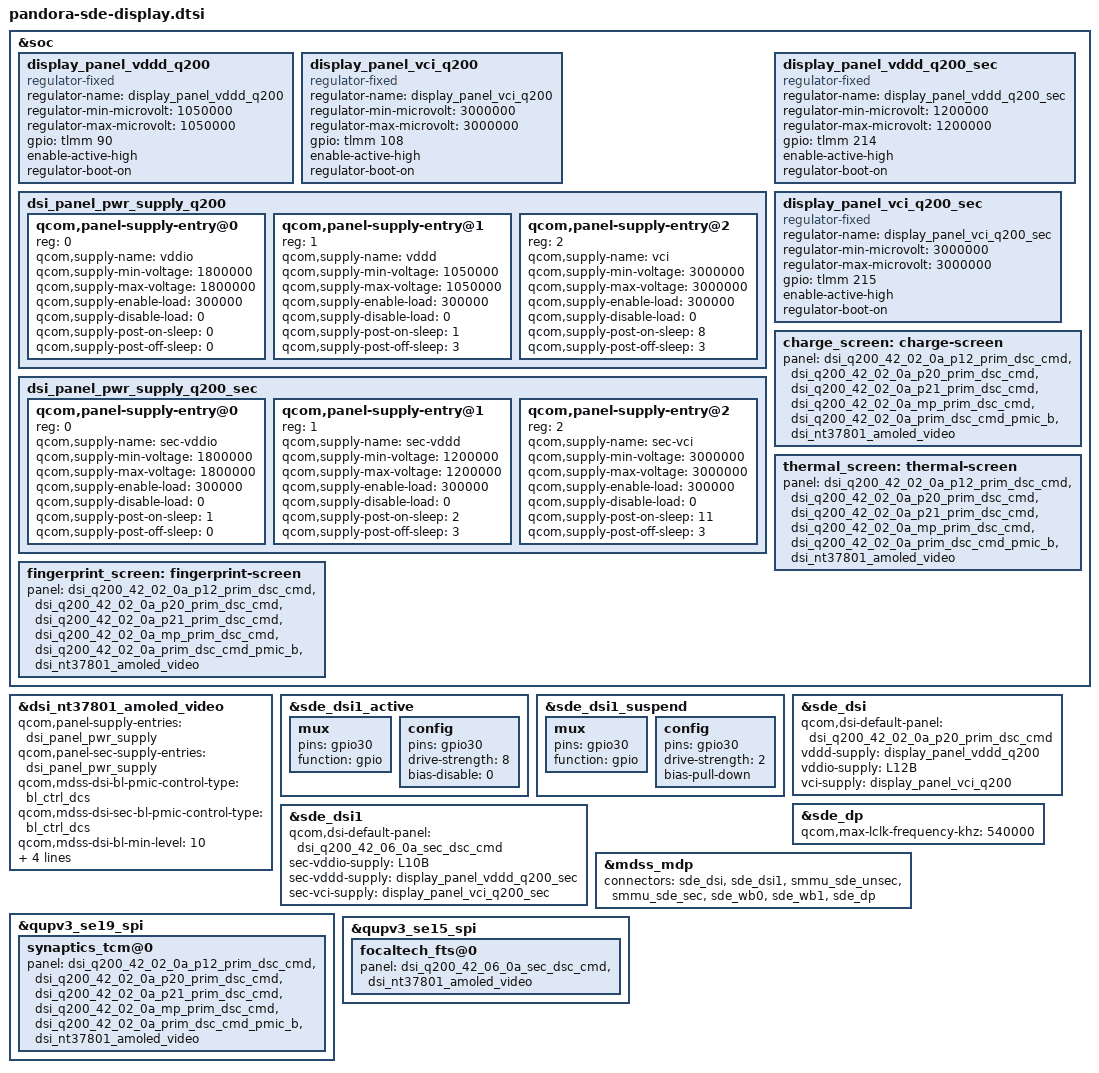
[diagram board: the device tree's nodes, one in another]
#include "canoe-sde-display.dtsi"
#include "dsi-panel-q200-42-02-0a-p12-prim-dsc-cmd.dtsi"
#include "dsi-panel-q200-42-02-0a-p20-prim-dsc-cmd.dtsi"
#include "dsi-panel-q200-42-02-0a-p21-prim-dsc-cmd.dtsi"
#include "dsi-panel-q200-42-02-0a-mp-prim-dsc-cmd.dtsi"
#include "dsi-panel-q200-42-02-0a-prim-dsc-cmd-pmic-b.dtsi"

#include "dsi-panel-q200-42-06-0a-sec-dsc-cmd.dtsi"

&soc {
	display_panel_vddd_q200: display_panel_vddd_q200 {
		compatible = "regulator-fixed";
		regulator-name = "display_panel_vddd_q200";
		regulator-min-microvolt = <1050000>;
		regulator-max-microvolt = <1050000>;
		gpio = <&tlmm 90 0>;
		enable-active-high;
		regulator-boot-on;
	};

    display_panel_vci_q200: display_panel_vci_q200 {
		compatible = "regulator-fixed";
		regulator-name = "display_panel_vci_q200";
		regulator-min-microvolt = <3000000>;
		regulator-max-microvolt = <3000000>;
		gpio = <&tlmm 108 0>;
		enable-active-high;
		regulator-boot-on;
	};

	dsi_panel_pwr_supply_q200: dsi_panel_pwr_supply_q200 {
		qcom,panel-supply-entry@0 {
			reg = <0>;
			qcom,supply-name = "vddio";
			qcom,supply-min-voltage = <1800000>;
			qcom,supply-max-voltage = <1800000>;
			qcom,supply-enable-load = <300000>;
			qcom,supply-disable-load = <0>;
			qcom,supply-post-on-sleep = <0>;
			qcom,supply-post-off-sleep = <0>;
		};
		qcom,panel-supply-entry@1 {
			reg = <1>;
			qcom,supply-name = "vddd";
			qcom,supply-min-voltage = <1050000>;
			qcom,supply-max-voltage = <1050000>;
			qcom,supply-enable-load = <300000>;
			qcom,supply-disable-load = <0>;
			qcom,supply-post-on-sleep = <1>;
			qcom,supply-post-off-sleep = <3>;
		};
		qcom,panel-supply-entry@2 {
			reg = <2>;
			qcom,supply-name = "vci";
			qcom,supply-min-voltage = <3000000>;
			qcom,supply-max-voltage = <3000000>;
			qcom,supply-enable-load = <300000>;
			qcom,supply-disable-load = <0>;
			qcom,supply-post-on-sleep = <8>;
			qcom,supply-post-off-sleep = <3>;
		};
	};

	display_panel_vddd_q200_sec: display_panel_vddd_q200_sec {
		compatible = "regulator-fixed";
		regulator-name = "display_panel_vddd_q200_sec";
		regulator-min-microvolt = <1200000>;
		regulator-max-microvolt = <1200000>;
		gpio = <&tlmm 214 0>;
		enable-active-high;
		regulator-boot-on;
	};

	display_panel_vci_q200_sec: display_panel_vci_q200_sec {
		compatible = "regulator-fixed";
		regulator-name = "display_panel_vci_q200_sec";
		regulator-min-microvolt = <3000000>;
		regulator-max-microvolt = <3000000>;
		gpio = <&tlmm 215 0>;
		enable-active-high;
		regulator-boot-on;
	};

	dsi_panel_pwr_supply_q200_sec: dsi_panel_pwr_supply_q200_sec {
		qcom,panel-supply-entry@0 {
			reg = <0>;
			qcom,supply-name = "sec-vddio";
			qcom,supply-min-voltage = <1800000>;
			qcom,supply-max-voltage = <1800000>;
			qcom,supply-enable-load = <300000>;
			qcom,supply-disable-load = <0>;
			qcom,supply-post-on-sleep = <1>;
			qcom,supply-post-off-sleep = <0>;
		};
		qcom,panel-supply-entry@1 {
			reg = <1>;
			qcom,supply-name = "sec-vddd";
			qcom,supply-min-voltage = <1200000>;
			qcom,supply-max-voltage = <1200000>;
			qcom,supply-enable-load = <300000>;
			qcom,supply-disable-load = <0>;
			qcom,supply-post-on-sleep = <2>;
			qcom,supply-post-off-sleep = <3>;
		};
		qcom,panel-supply-entry@2 {
			reg = <2>;
			qcom,supply-name = "sec-vci";
			qcom,supply-min-voltage = <3000000>;
			qcom,supply-max-voltage = <3000000>;
			qcom,supply-enable-load = <300000>;
			qcom,supply-disable-load = <0>;
			qcom,supply-post-on-sleep = <11>;
			qcom,supply-post-off-sleep = <3>;
		};
	};
};
&dsi_nt37801_amoled_video {
       qcom,panel-supply-entries = <&dsi_panel_pwr_supply>;
       qcom,panel-sec-supply-entries = <&dsi_panel_pwr_supply>;
       qcom,mdss-dsi-bl-pmic-control-type = "bl_ctrl_dcs";
       qcom,mdss-dsi-sec-bl-pmic-control-type = "bl_ctrl_dcs";
       qcom,mdss-dsi-bl-min-level = <10>;
       qcom,mdss-dsi-bl-max-level = <4095>;
       qcom,mdss-brightness-max-level = <8191>;
       qcom,mdss-dsi-bl-inverted-dbv;
       qcom,platform-sec-reset-gpio = <&tlmm 30 0>;
};

&sde_dsi1_active {
	mux {
		pins = "gpio30";
		function = "gpio";
	};

	config {
		pins = "gpio30";
		drive-strength = <8>;   /* 8 mA */
		bias-disable = <0>;   /* no pull */
	};
};

&sde_dsi1_suspend {
	mux {
		pins = "gpio30";
		function = "gpio";
	};

	config {
		pins = "gpio30";
		drive-strength = <2>;   /* 2 mA */
		bias-pull-down;         /* PULL DOWN */
	};
};

&sde_dsi {
	qcom,dsi-default-panel = <&dsi_q200_42_02_0a_p20_prim_dsc_cmd>;
	vddd-supply = <&display_panel_vddd_q200>;
	vddio-supply = <&L12B>;
	vci-supply = <&display_panel_vci_q200>;

	/delete-property/ tvdd-supply;
};

&sde_dsi1 {
	qcom,dsi-default-panel = <&dsi_q200_42_06_0a_sec_dsc_cmd>;
	sec-vddio-supply = <&L10B>;
	sec-vddd-supply = <&display_panel_vddd_q200_sec>;
	sec-vci-supply = <&display_panel_vci_q200_sec>;

	/delete-property/ tvdd-supply;
	/delete-property/ vddd-supply;
	/delete-property/ vddio-supply;
	/delete-property/ vci-supply;

	status = "ok";
};

&sde_dp {
	qcom,max-lclk-frequency-khz = <540000>;
	status = "ok";
};

&mdss_mdp {
	connectors = <&sde_dsi &sde_dsi1 &smmu_sde_unsec &smmu_sde_sec &sde_wb0 &sde_wb1 &sde_dp>;
};

&qupv3_se19_spi {
	synaptics_tcm@0 {
		panel = <&dsi_q200_42_02_0a_p12_prim_dsc_cmd
			&dsi_q200_42_02_0a_p20_prim_dsc_cmd
			&dsi_q200_42_02_0a_p21_prim_dsc_cmd
			&dsi_q200_42_02_0a_mp_prim_dsc_cmd
			&dsi_q200_42_02_0a_prim_dsc_cmd_pmic_b
			&dsi_nt37801_amoled_video>;
	};
};

&qupv3_se15_spi {
	focaltech_fts@0 {
		panel = <&dsi_q200_42_06_0a_sec_dsc_cmd
			&dsi_nt37801_amoled_video>;
	};
};

&soc {
	charge_screen: charge-screen {
		panel = <&dsi_q200_42_02_0a_p12_prim_dsc_cmd
			&dsi_q200_42_02_0a_p20_prim_dsc_cmd
			&dsi_q200_42_02_0a_p21_prim_dsc_cmd
			&dsi_q200_42_02_0a_mp_prim_dsc_cmd
			&dsi_q200_42_02_0a_prim_dsc_cmd_pmic_b
			&dsi_nt37801_amoled_video>;
	};
	thermal_screen: thermal-screen {
		panel = <&dsi_q200_42_02_0a_p12_prim_dsc_cmd
			&dsi_q200_42_02_0a_p20_prim_dsc_cmd
			&dsi_q200_42_02_0a_p21_prim_dsc_cmd
			&dsi_q200_42_02_0a_mp_prim_dsc_cmd
			&dsi_q200_42_02_0a_prim_dsc_cmd_pmic_b
			&dsi_nt37801_amoled_video>;
	};
	fingerprint_screen: fingerprint-screen {
		panel = <&dsi_q200_42_02_0a_p12_prim_dsc_cmd
			&dsi_q200_42_02_0a_p20_prim_dsc_cmd
			&dsi_q200_42_02_0a_p21_prim_dsc_cmd
			&dsi_q200_42_02_0a_mp_prim_dsc_cmd
			&dsi_q200_42_02_0a_prim_dsc_cmd_pmic_b
			&dsi_nt37801_amoled_video>;
	};
};
